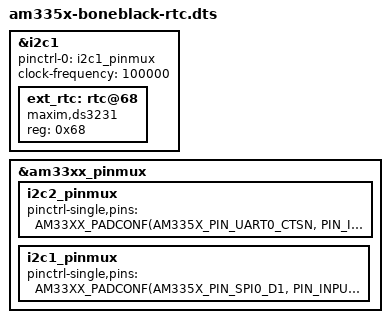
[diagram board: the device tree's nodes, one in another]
/**
 * @file am335x-boneblack-rtc.dts
 * @author Felipe Jimenez <felipea.jimenezc@gmail.com>
 * @date 27/07/2023
**/

/dts-v1/;
#include "am335x-boneblack.dts"

&i2c1 {
    pinctrl-names = "default";
    pinctrl-0 = <&i2c1_pinmux>;
    clock-frequency = <100000>;
    status = "okay";

    ext_rtc: rtc@68 {
        compatible = "maxim,ds3231";
        reg = <0x68>;
    };
};

&am33xx_pinmux {
    i2c2_pinmux: i2c2_pinmux {
        pinctrl-single,pins = <
            AM33XX_PADCONF(AM335X_PIN_UART0_CTSN, PIN_INPUT_PULLUP, MUX_MODE3)    /* uart1_rtsn.i2c1_sda */
            AM33XX_PADCONF(AM335X_PIN_UART0_RTSN, PIN_INPUT_PULLUP, MUX_MODE3)    /* spi0_cs0.i2c1_scl */
        >;
    };
    i2c1_pinmux: i2c1_pinmux {
        pinctrl-single,pins = <
            AM33XX_PADCONF(AM335X_PIN_SPI0_D1, PIN_INPUT_PULLUP, MUX_MODE2) /* spi0_d1.12c1_sda */
            AM33XX_PADCONF(AM335X_PIN_SPI0_CS0, PIN_INPUT_PULLUP, MUX_MODE2) /* spi0_cs0.12c1_scl */
        >;
    };
};
